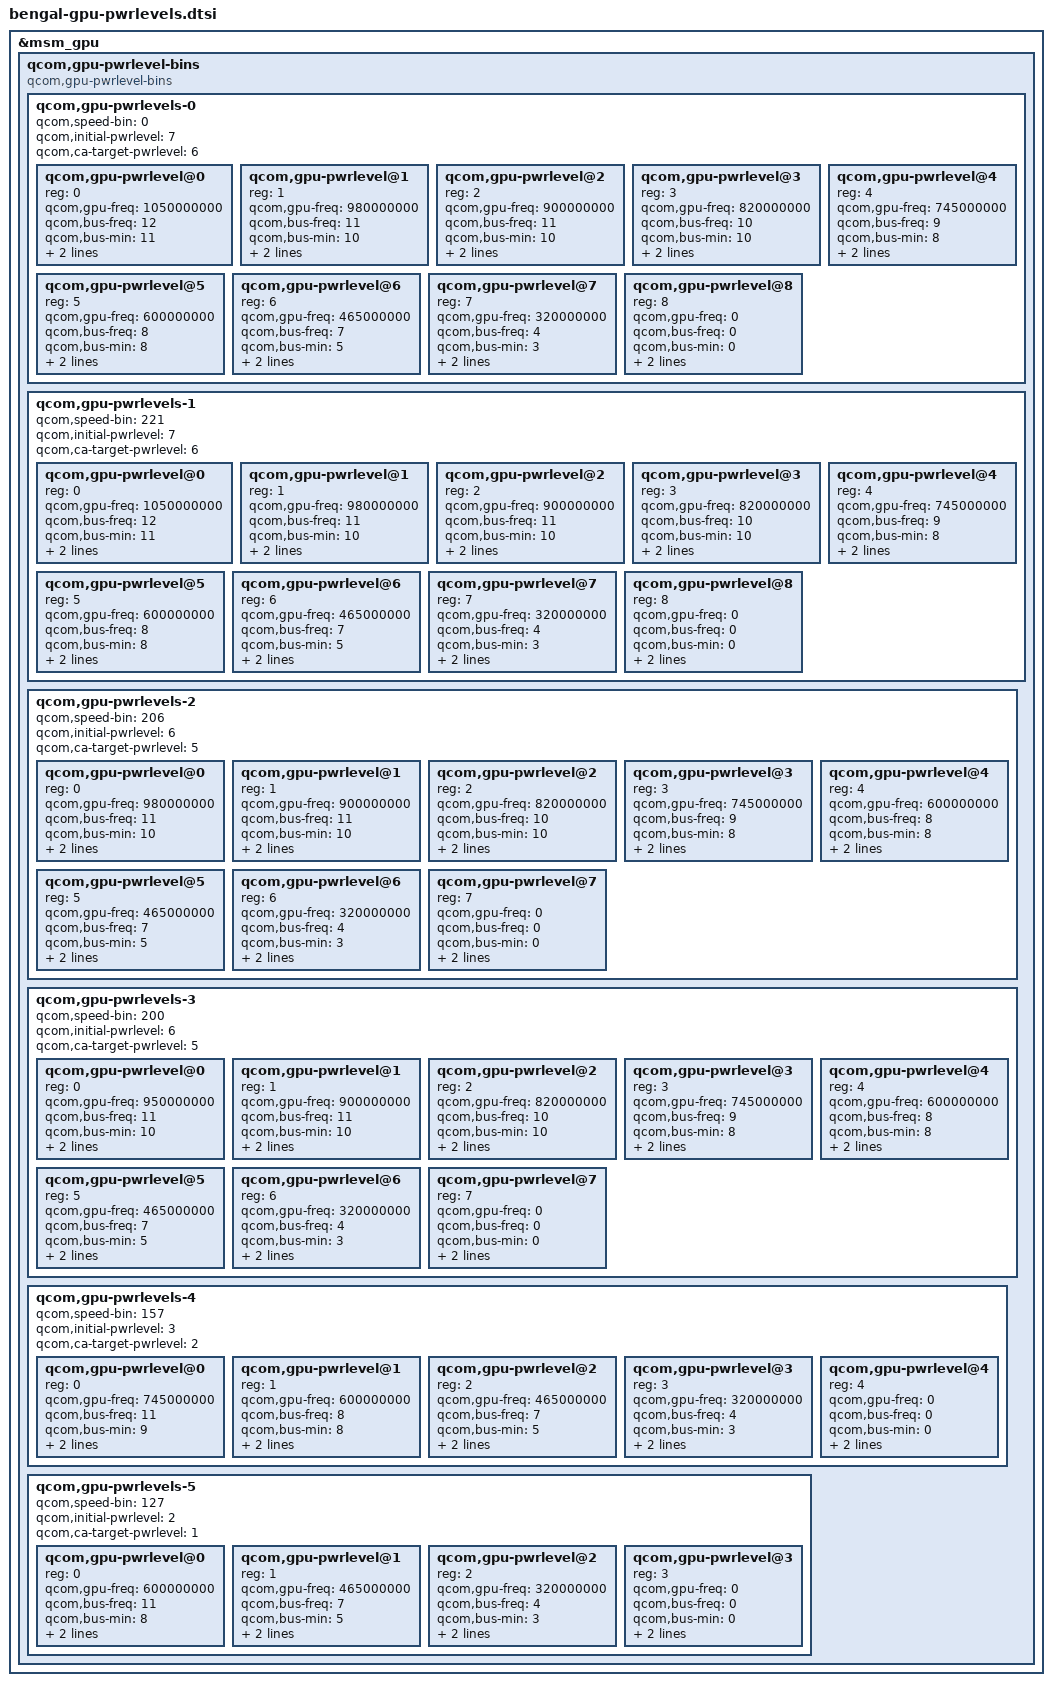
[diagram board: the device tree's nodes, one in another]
&msm_gpu {
	qcom,gpu-pwrlevel-bins {
		#address-cells = <1>;
		#size-cells = <0>;

		compatible = "qcom,gpu-pwrlevel-bins";

		qcom,gpu-pwrlevels-0 {
			#address-cells = <1>;
			#size-cells = <0>;

			qcom,speed-bin = <0>;

			qcom,initial-pwrlevel = <7>;
			qcom,ca-target-pwrlevel = <6>;

			/* SUPER TURBO */
			qcom,gpu-pwrlevel@0 {
				reg = <0>;
				qcom,gpu-freq = <1050000000>;
				qcom,bus-freq = <12>;
				qcom,bus-min = <11>;
				qcom,bus-max = <12>;
				qcom,level = <RPMH_REGULATOR_LEVEL_SUPER_TURBO>;
			};

			/* TURBO_L1 */
			qcom,gpu-pwrlevel@1 {
				reg = <1>;
				qcom,gpu-freq = <980000000>;
				qcom,bus-freq = <11>;
				qcom,bus-min = <10>;
				qcom,bus-max = <11>;
				qcom,level = <RPMH_REGULATOR_LEVEL_TURBO_L1>;
			};

			/* TURBO */
			qcom,gpu-pwrlevel@2 {
				reg = <2>;
				qcom,gpu-freq = <900000000>;
				qcom,bus-freq = <11>;
				qcom,bus-min = <10>;
				qcom,bus-max = <11>;
				qcom,level = <RPMH_REGULATOR_LEVEL_TURBO>;
			};

			/* NOM_L1 */
			qcom,gpu-pwrlevel@3 {
				reg = <3>;
				qcom,gpu-freq = <820000000>;
				qcom,bus-freq = <10>;
				qcom,bus-min = <10>;
				qcom,bus-max = <11>;
				qcom,level = <RPMH_REGULATOR_LEVEL_NOM_L1>;
			};

			/* NOM */
			qcom,gpu-pwrlevel@4 {
				reg = <4>;
				qcom,gpu-freq = <745000000>;
				qcom,bus-freq = <9>;
				qcom,bus-min = <8>;
				qcom,bus-max = <10>;
				qcom,level = <RPMH_REGULATOR_LEVEL_NOM>;
			};

			/* SVS_L1 */
			qcom,gpu-pwrlevel@5 {
				reg = <5>;
				qcom,gpu-freq = <600000000>;
				qcom,bus-freq = <8>;
				qcom,bus-min = <8>;
				qcom,bus-max = <9>;
				qcom,level = <RPMH_REGULATOR_LEVEL_SVS_L1>;
			};

			/* SVS */
			qcom,gpu-pwrlevel@6 {
				reg = <6>;
				qcom,gpu-freq = <465000000>;
				qcom,bus-freq = <7>;
				qcom,bus-min = <5>;
				qcom,bus-max = <8>;
				qcom,level = <RPMH_REGULATOR_LEVEL_SVS>;
			};

			/* LOW SVS */
			qcom,gpu-pwrlevel@7 {
				reg = <7>;
				qcom,gpu-freq = <320000000>;
				qcom,bus-freq = <4>;
				qcom,bus-min = <3>;
				qcom,bus-max = <5>;
				qcom,level = <RPMH_REGULATOR_LEVEL_LOW_SVS>;
			};

			/* XO */
			qcom,gpu-pwrlevel@8 {
				reg = <8>;
				qcom,gpu-freq = <0>;
				qcom,bus-freq = <0>;
				qcom,bus-min = <0>;
				qcom,bus-max = <0>;
				qcom,level = <RPMH_REGULATOR_LEVEL_LOW_SVS>;
			};
		};

		qcom,gpu-pwrlevels-1 {
			#address-cells = <1>;
			#size-cells = <0>;

			qcom,speed-bin = <221>;

			qcom,initial-pwrlevel = <7>;
			qcom,ca-target-pwrlevel = <6>;

			/* SUPER TURBO */
			qcom,gpu-pwrlevel@0 {
				reg = <0>;
				qcom,gpu-freq = <1050000000>;
				qcom,bus-freq = <12>;
				qcom,bus-min = <11>;
				qcom,bus-max = <12>;
				qcom,level = <RPMH_REGULATOR_LEVEL_SUPER_TURBO>;
			};

			/* TURBO_L1 */
			qcom,gpu-pwrlevel@1 {
				reg = <1>;
				qcom,gpu-freq = <980000000>;
				qcom,bus-freq = <11>;
				qcom,bus-min = <10>;
				qcom,bus-max = <11>;
				qcom,level = <RPMH_REGULATOR_LEVEL_TURBO_L1>;
			};

			/* TURBO */
			qcom,gpu-pwrlevel@2 {
				reg = <2>;
				qcom,gpu-freq = <900000000>;
				qcom,bus-freq = <11>;
				qcom,bus-min = <10>;
				qcom,bus-max = <11>;
				qcom,level = <RPMH_REGULATOR_LEVEL_TURBO>;
			};

			/* NOM_L1 */
			qcom,gpu-pwrlevel@3 {
				reg = <3>;
				qcom,gpu-freq = <820000000>;
				qcom,bus-freq = <10>;
				qcom,bus-min = <10>;
				qcom,bus-max = <11>;
				qcom,level = <RPMH_REGULATOR_LEVEL_NOM_L1>;
			};

			/* NOM */
			qcom,gpu-pwrlevel@4 {
				reg = <4>;
				qcom,gpu-freq = <745000000>;
				qcom,bus-freq = <9>;
				qcom,bus-min = <8>;
				qcom,bus-max = <10>;
				qcom,level = <RPMH_REGULATOR_LEVEL_NOM>;
			};

			/* SVS_L1 */
			qcom,gpu-pwrlevel@5 {
				reg = <5>;
				qcom,gpu-freq = <600000000>;
				qcom,bus-freq = <8>;
				qcom,bus-min = <8>;
				qcom,bus-max = <9>;
				qcom,level = <RPMH_REGULATOR_LEVEL_SVS_L1>;
			};

			/* SVS */
			qcom,gpu-pwrlevel@6 {
				reg = <6>;
				qcom,gpu-freq = <465000000>;
				qcom,bus-freq = <7>;
				qcom,bus-min = <5>;
				qcom,bus-max = <8>;
				qcom,level = <RPMH_REGULATOR_LEVEL_SVS>;
			};

			/* LOW SVS */
			qcom,gpu-pwrlevel@7 {
				reg = <7>;
				qcom,gpu-freq = <320000000>;
				qcom,bus-freq = <4>;
				qcom,bus-min = <3>;
				qcom,bus-max = <5>;
				qcom,level = <RPMH_REGULATOR_LEVEL_LOW_SVS>;
			};

			/* XO */
			qcom,gpu-pwrlevel@8 {
				reg = <8>;
				qcom,gpu-freq = <0>;
				qcom,bus-freq = <0>;
				qcom,bus-min = <0>;
				qcom,bus-max = <0>;
				qcom,level = <RPMH_REGULATOR_LEVEL_LOW_SVS>;
			};
		};

		qcom,gpu-pwrlevels-2 {
			#address-cells = <1>;
			#size-cells = <0>;

			qcom,speed-bin = <206>;

			qcom,initial-pwrlevel = <6>;
			qcom,ca-target-pwrlevel = <5>;

			/* TURBO_L1 */
			qcom,gpu-pwrlevel@0 {
				reg = <0>;
				qcom,gpu-freq = <980000000>;
				qcom,bus-freq = <11>;
				qcom,bus-min = <10>;
				qcom,bus-max = <11>;
				qcom,level = <RPMH_REGULATOR_LEVEL_TURBO_L1>;
			};

			/* TURBO */
			qcom,gpu-pwrlevel@1 {
				reg = <1>;
				qcom,gpu-freq = <900000000>;
				qcom,bus-freq = <11>;
				qcom,bus-min = <10>;
				qcom,bus-max = <11>;
				qcom,level = <RPMH_REGULATOR_LEVEL_TURBO>;
			};

			/* NOM_L1 */
			qcom,gpu-pwrlevel@2 {
				reg = <2>;
				qcom,gpu-freq = <820000000>;
				qcom,bus-freq = <10>;
				qcom,bus-min = <10>;
				qcom,bus-max = <11>;
				qcom,level = <RPMH_REGULATOR_LEVEL_NOM_L1>;
			};

			/* NOM */
			qcom,gpu-pwrlevel@3 {
				reg = <3>;
				qcom,gpu-freq = <745000000>;
				qcom,bus-freq = <9>;
				qcom,bus-min = <8>;
				qcom,bus-max = <10>;
				qcom,level = <RPMH_REGULATOR_LEVEL_NOM>;
			};

			/* SVS_L1 */
			qcom,gpu-pwrlevel@4 {
				reg = <4>;
				qcom,gpu-freq = <600000000>;
				qcom,bus-freq = <8>;
				qcom,bus-min = <8>;
				qcom,bus-max = <9>;
				qcom,level = <RPMH_REGULATOR_LEVEL_SVS_L1>;
			};

			/* SVS */
			qcom,gpu-pwrlevel@5 {
				reg = <5>;
				qcom,gpu-freq = <465000000>;
				qcom,bus-freq = <7>;
				qcom,bus-min = <5>;
				qcom,bus-max = <8>;
				qcom,level = <RPMH_REGULATOR_LEVEL_SVS>;
			};

			/* LOW SVS */
			qcom,gpu-pwrlevel@6 {
				reg = <6>;
				qcom,gpu-freq = <320000000>;
				qcom,bus-freq = <4>;
				qcom,bus-min = <3>;
				qcom,bus-max = <5>;
				qcom,level = <RPMH_REGULATOR_LEVEL_LOW_SVS>;
			};

			/* XO */
			qcom,gpu-pwrlevel@7 {
				reg = <7>;
				qcom,gpu-freq = <0>;
				qcom,bus-freq = <0>;
				qcom,bus-min = <0>;
				qcom,bus-max = <0>;
				qcom,level = <RPMH_REGULATOR_LEVEL_LOW_SVS>;
			};
		};

		qcom,gpu-pwrlevels-3 {
			#address-cells = <1>;
			#size-cells = <0>;

			qcom,speed-bin = <200>;

			qcom,initial-pwrlevel = <6>;
			qcom,ca-target-pwrlevel = <5>;

			/* TURBO_L1 */
			qcom,gpu-pwrlevel@0 {
				reg = <0>;
				qcom,gpu-freq = <950000000>;
				qcom,bus-freq = <11>;
				qcom,bus-min = <10>;
				qcom,bus-max = <11>;
				qcom,level = <RPMH_REGULATOR_LEVEL_TURBO_L1>;
			};

			/* TURBO */
			qcom,gpu-pwrlevel@1 {
				reg = <1>;
				qcom,gpu-freq = <900000000>;
				qcom,bus-freq = <11>;
				qcom,bus-min = <10>;
				qcom,bus-max = <11>;
				qcom,level = <RPMH_REGULATOR_LEVEL_TURBO>;
			};

			/* NOM_L1 */
			qcom,gpu-pwrlevel@2 {
				reg = <2>;
				qcom,gpu-freq = <820000000>;
				qcom,bus-freq = <10>;
				qcom,bus-min = <10>;
				qcom,bus-max = <11>;
				qcom,level = <RPMH_REGULATOR_LEVEL_NOM_L1>;
			};

			/* NOM */
			qcom,gpu-pwrlevel@3 {
				reg = <3>;
				qcom,gpu-freq = <745000000>;
				qcom,bus-freq = <9>;
				qcom,bus-min = <8>;
				qcom,bus-max = <10>;
				qcom,level = <RPMH_REGULATOR_LEVEL_NOM>;
			};

			/* SVS_L1 */
			qcom,gpu-pwrlevel@4 {
				reg = <4>;
				qcom,gpu-freq = <600000000>;
				qcom,bus-freq = <8>;
				qcom,bus-min = <8>;
				qcom,bus-max = <9>;
				qcom,level = <RPMH_REGULATOR_LEVEL_SVS_L1>;
			};

			/* SVS */
			qcom,gpu-pwrlevel@5 {
				reg = <5>;
				qcom,gpu-freq = <465000000>;
				qcom,bus-freq = <7>;
				qcom,bus-min = <5>;
				qcom,bus-max = <8>;
				qcom,level = <RPMH_REGULATOR_LEVEL_SVS>;
			};

			/* LOW SVS */
			qcom,gpu-pwrlevel@6 {
				reg = <6>;
				qcom,gpu-freq = <320000000>;
				qcom,bus-freq = <4>;
				qcom,bus-min = <3>;
				qcom,bus-max = <5>;
				qcom,level = <RPMH_REGULATOR_LEVEL_LOW_SVS>;
			};

			/* XO */
			qcom,gpu-pwrlevel@7 {
				reg = <7>;
				qcom,gpu-freq = <0>;
				qcom,bus-freq = <0>;
				qcom,bus-min = <0>;
				qcom,bus-max = <0>;
				qcom,level = <RPMH_REGULATOR_LEVEL_LOW_SVS>;
			};
		};

		qcom,gpu-pwrlevels-4 {
			#address-cells = <1>;
			#size-cells = <0>;

			qcom,speed-bin = <157>;

			qcom,initial-pwrlevel = <3>;
			qcom,ca-target-pwrlevel = <2>;

			/* NOM */
			qcom,gpu-pwrlevel@0 {
				reg = <0>;
				qcom,gpu-freq = <745000000>;
				qcom,bus-freq = <11>;
				qcom,bus-min = <9>;
				qcom,bus-max = <11>;
				qcom,level = <RPMH_REGULATOR_LEVEL_NOM>;
			};

			/* SVS_L1 */
			qcom,gpu-pwrlevel@1 {
				reg = <1>;
				qcom,gpu-freq = <600000000>;
				qcom,bus-freq = <8>;
				qcom,bus-min = <8>;
				qcom,bus-max = <10>;
				qcom,level = <RPMH_REGULATOR_LEVEL_SVS_L1>;
			};

			/* SVS */
			qcom,gpu-pwrlevel@2 {
				reg = <2>;
				qcom,gpu-freq = <465000000>;
				qcom,bus-freq = <7>;
				qcom,bus-min = <5>;
				qcom,bus-max = <8>;
				qcom,level = <RPMH_REGULATOR_LEVEL_SVS>;
			};

			/* LOW SVS */
			qcom,gpu-pwrlevel@3 {
				reg = <3>;
				qcom,gpu-freq = <320000000>;
				qcom,bus-freq = <4>;
				qcom,bus-min = <3>;
				qcom,bus-max = <5>;
				qcom,level = <RPMH_REGULATOR_LEVEL_LOW_SVS>;
			};

			/* XO */
			qcom,gpu-pwrlevel@4 {
				reg = <4>;
				qcom,gpu-freq = <0>;
				qcom,bus-freq = <0>;
				qcom,bus-min = <0>;
				qcom,bus-max = <0>;
				qcom,level = <RPMH_REGULATOR_LEVEL_LOW_SVS>;
			};
		};

		qcom,gpu-pwrlevels-5 {
			#address-cells = <1>;
			#size-cells = <0>;

			qcom,speed-bin = <127>;

			qcom,initial-pwrlevel = <2>;
			qcom,ca-target-pwrlevel = <1>;

			/* SVS_L1 */
			qcom,gpu-pwrlevel@0 {
				reg = <0>;
				qcom,gpu-freq = <600000000>;
				qcom,bus-freq = <11>;
				qcom,bus-min = <8>;
				qcom,bus-max = <11>;
				qcom,level = <RPMH_REGULATOR_LEVEL_SVS_L1>;
			};

			/* SVS */
			qcom,gpu-pwrlevel@1 {
				reg = <1>;
				qcom,gpu-freq = <465000000>;
				qcom,bus-freq = <7>;
				qcom,bus-min = <5>;
				qcom,bus-max = <9>;
				qcom,level = <RPMH_REGULATOR_LEVEL_SVS>;
			};

			/* LOW SVS */
			qcom,gpu-pwrlevel@2 {
				reg = <2>;
				qcom,gpu-freq = <320000000>;
				qcom,bus-freq = <4>;
				qcom,bus-min = <3>;
				qcom,bus-max = <5>;
				qcom,level = <RPMH_REGULATOR_LEVEL_LOW_SVS>;
			};

			/* XO */
			qcom,gpu-pwrlevel@3 {
				reg = <3>;
				qcom,gpu-freq = <0>;
				qcom,bus-freq = <0>;
				qcom,bus-min = <0>;
				qcom,bus-max = <0>;
				qcom,level = <RPMH_REGULATOR_LEVEL_LOW_SVS>;
			};
		};

	};
};
